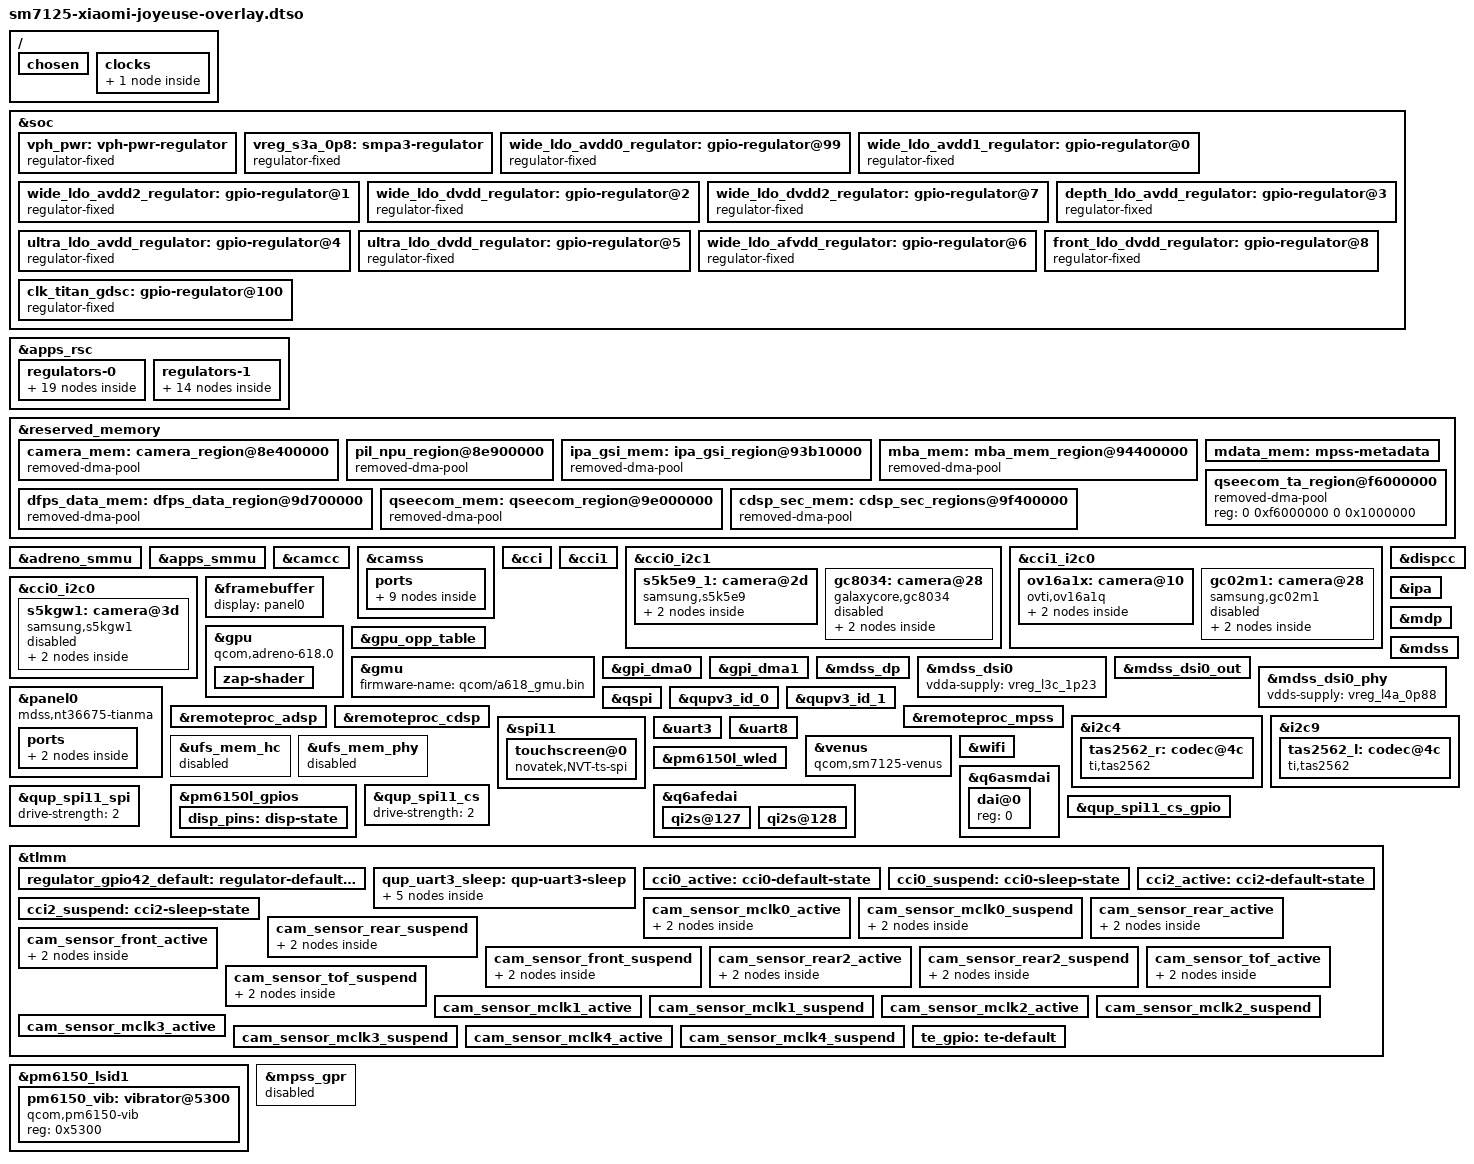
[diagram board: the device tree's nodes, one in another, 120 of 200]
// SPDX-License-Identifier: (GPL-2.0+ OR MIT)

/dts-v1/;

#if 0
/* dt overlay */
/plugin/;
#else
#include "sm7125-xiaomi-joyeuse.dts"
#endif
#include "sm7125-xiaomi-joyeuse-overlay.dtsi"

/ {
	chosen {
		#address-cells = <2>;
		#size-cells = <2>;
		ranges;

		//TODO: remove unneeded once all sorta out.
		bootargs = "pd_ignore_unused no_console_suspend kpti=off nokaslr ignore_loglevel clk_ignore_unused";

		stdout-path = "serial0:115200n8";
	};

	//reserved_memory: reserved_memory {};

	/* place-holder incase need a new fixed clk */
	clocks: clocks {
	        clk_titan_gdsc {
			compatible = "fixed-clock";
			clock-frequency = <38400000>;
			#clock-cells = <0>;
	        };
	};
};

&soc {
	vph_pwr: vph-pwr-regulator {
		compatible = "regulator-fixed";
		regulator-name = "vph_pwr";
		regulator-min-microvolt = <3700000>;
		regulator-max-microvolt = <3700000>;
	};

	vreg_s3a_0p8: smpa3-regulator {
		compatible = "regulator-fixed";
		regulator-name = "vreg_s3a_0p8";

		regulator-min-microvolt = <800000>;
		regulator-max-microvolt = <800000>;
		regulator-always-on;
		vin-supply = <&vph_pwr>;
	};
#if 1
	wide_ldo_avdd0_regulator: gpio-regulator@99 { //AVDD0 2.9V //AVDD0_2.8V
                compatible = "regulator-fixed";
                regulator-name = "wide_ldo_avdd0_regulator";
                regulator-min-microvolt = <2800000>;
                regulator-max-microvolt = <2800000>;
                regulator-enable-ramp-delay = <100>;
                enable-active-high;
                gpio = <&pm6150l_gpios 4 0>; /* schematic not connected */
                vin-supply = <&vreg_bob>;
        };

        wide_ldo_avdd1_regulator: gpio-regulator@0 { //AVDD1 2.9V //AVDD0_2.8V
                compatible = "regulator-fixed";
                regulator-name = "wide_ldo_avdd1_regulator";
                regulator-min-microvolt = <2800000>;
                regulator-max-microvolt = <2800000>;
                regulator-enable-ramp-delay = <100>;
                enable-active-high;
                gpio = <&pm6150l_gpios 9 0>; 
		/* 
		* another gpio4 called avdd1_2p8 but schematic not connected 
		* and the name is swapped to avdd0 accordingly.
		*/
                vin-supply = <&vreg_bob>;
        };

        wide_ldo_avdd2_regulator: gpio-regulator@1 { //AVDD2 1.8V //2M_DVDDIO_1.8V?
                compatible = "regulator-fixed";
                regulator-name = "wide_ldo_avdd2_regulator";
                regulator-min-microvolt = <1800000>;
                regulator-max-microvolt = <1800000>;
                regulator-enable-ramp-delay = <100>;
                enable-active-high;
                gpio = <&pm6150l_gpios 12 0>; //for P0,demo is tlmm 63 //TODO
                vin-supply = <&vreg_bob>; //TODO
        };

        wide_ldo_dvdd_regulator: gpio-regulator@2 { //DVDD 1.2V
                compatible = "regulator-fixed";
                regulator-name = "wide_ldo_dvdd_regulator";
                regulator-min-microvolt = <1200000>;
                regulator-max-microvolt = <1200000>;
                regulator-enable-ramp-delay = <100>;
                enable-active-high;
                gpio = <&tlmm 42 0>;
                vin-supply = <&vreg_s5a>;//48M pm6150_s5
        };

        wide_ldo_dvdd2_regulator: gpio-regulator@7 { //DVDD2 1.05V
                compatible = "regulator-fixed";
                regulator-name = "wide_ldo_dvdd2_regulator";
                regulator-min-microvolt = <1050000>;
                regulator-max-microvolt = <1050000>;
                regulator-enable-ramp-delay = <100>;
                enable-active-high;
                gpio = <&tlmm 42 0>;
                vin-supply = <&vreg_s8c>;//64M pm6150l_s8 + pm6150_s5a
        };

        depth_ldo_avdd_regulator: gpio-regulator@3 { //depth AVDD 2.8V
                compatible = "regulator-fixed";
                regulator-name = "depth_ldo_avdd_regulator";
                regulator-min-microvolt = <2800000>;
                regulator-max-microvolt = <2800000>;
                regulator-enable-ramp-delay = <100>;
                enable-active-high;
                gpio = <&tlmm 43 0>;
                vin-supply = <&vreg_bob>;
        };

        ultra_ldo_avdd_regulator: gpio-regulator@4 { //ultra AVDD 2.8V
                compatible = "regulator-fixed";
                //reg = <0x04 0x00>;
                regulator-name = "ultra_ldo_avdd_regulator";
                regulator-min-microvolt = <2800000>;
                regulator-max-microvolt = <2800000>;
                regulator-enable-ramp-delay = <100>;
                enable-active-high;
                gpio = <&pm6150l_gpios 8 0>;//for p0 main band
                vin-supply = <&vreg_bob>;
        };

        ultra_ldo_dvdd_regulator: gpio-regulator@5 { //ultra DVDD 2.8V
                compatible = "regulator-fixed";
                regulator-name = "ultra_ldo_dvdd_regulator";
                regulator-min-microvolt = <1200000>;
                regulator-max-microvolt = <1200000>;
                regulator-enable-ramp-delay = <100>;
                enable-active-high;
                gpio = <&tlmm 72 0>;
                vin-supply = <&vreg_s5a>;
        };

        wide_ldo_afvdd_regulator: gpio-regulator@6 { //AFVDD 2.8V
                compatible = "regulator-fixed";
                regulator-name = "wide_ldo_afvdd_regulator";
                regulator-min-microvolt = <2800000>;
                regulator-max-microvolt = <2800000>;
                regulator-enable-ramp-delay = <100>;
                enable-active-high;
                gpio = <&pm6150l_gpios 6 0>;
                vin-supply = <&vreg_bob>; //TODO
        };

        front_ldo_dvdd_regulator: gpio-regulator@8 { //dvdd1.1v-20
                compatible = "regulator-fixed";
                regulator-name = "front_ldo_dvdd_regulator";
                regulator-min-microvolt = <1050000>;
                regulator-max-microvolt = <1050000>;
                regulator-enable-ramp-delay = <100>;
                enable-active-high;
                gpio = <&tlmm 117 0>;
                vin-supply = <&vreg_s5a>;
        };
#endif
        clk_titan_gdsc: gpio-regulator@100 { //dummy gdsc
                compatible = "regulator-fixed";
                //reg = <0x08 0x00>;
                regulator-name = "clk_titan_gdsc";
                regulator-min-microvolt = <1050000>;
                regulator-max-microvolt = <1050000>;
                regulator-enable-ramp-delay = <100>;
        };
};

&apps_rsc {
	regulators-0 {	
		vdd-s1-supply = <&vph_pwr>;
		vdd-s2-supply = <&vph_pwr>;
		vdd-s3-supply = <&vph_pwr>;
		vdd-s4-supply = <&vph_pwr>;
		vdd-s5-supply = <&vph_pwr>;

		vreg_s4a_1p1: smps4 {
			regulator-min-microvolt = <824000>;
			regulator-max-microvolt = <1120000>;
		};

		vreg_s5a:
		vreg_s5a_2p0: smps5 {
			regulator-min-microvolt = <1744000>;
			regulator-max-microvolt = <2040000>;
		};

		vreg_l1a_1p2: ldo1 {
			regulator-min-microvolt = <1178000>;
			regulator-max-microvolt = <1256000>;
		};

		vreg_l2a_1p0: ldo2 {
			regulator-min-microvolt = <944000>;
			regulator-max-microvolt = <1056000>;
		};

		vdda_pll_cc_ebi01:
		vreg_l3a_1p0: ldo3 {
			regulator-min-microvolt = <968000>;
			regulator-max-microvolt = <1064000>;
		};

		vdd_qlink_lv:
		vdd_qlink_lv_ck:
		vdd_usb_hs_core:
		vdda_mipi_csi0_0p9:
		vdda_mipi_csi1_0p9:
		vdda_mipi_csi2_0p9:
		vdda_mipi_csi3_0p9:
		vdda_mipi_dsi0_pll:
		vdda_mipi_dsi1_pll:
		vdda_qrefs_0p9:
		vdda_ufs_core:
		vdda_usb_ss_dp_core:
		vreg_l4a_0p88: ldo4 {
			regulator-min-microvolt = <824000>;
			regulator-max-microvolt = <924000>;
		};

		vreg_l5a_2p7: ldo5 {
			regulator-min-microvolt = <2600000>;
			regulator-max-microvolt = <2800000>;
		};

		vreg_l6a_1p2: ldo6 {
			regulator-min-microvolt = <568000>;
			regulator-max-microvolt = <648000>;			
		};

		vdd_wcss_cx:
		vreg_l9a_0p8: ldo9 {
			regulator-min-microvolt = <624000>;
			regulator-max-microvolt = <800000>;
		};

		vddpx_3:
		vreg_l10a_1p8: ldo10 {
			regulator-min-microvolt = <1800000>;
			regulator-max-microvolt = <1832000>;
		};

		vdd_qfprom:
		vdda_apc1_cs_1p8:
		vdda_qrefs_1p8:
		vdda_usb_hs_1p8:
		vddpx_11:
		vreg_l11a_1p8: ldo11 {
			regulator-min-microvolt = <1696000>;
			regulator-max-microvolt = <1904000>;
		};

		vreg_l12a_1p8: ldo12 {
			regulator-min-microvolt = <1696000>;
			regulator-max-microvolt = <1952000>;
		};

		/* 3p0 <- 800ohm -> 1p8 */
		vreg_l13a_1p8: ldo13 {
			regulator-min-microvolt = <1696000>;
			regulator-max-microvolt = <1904000>;
		};

		vreg_l14a_1p8: ldo14 {
			regulator-min-microvolt = <1720000>;
			regulator-max-microvolt = <1832000>;
		};

		vreg_l15a_1p8: ldo15 {
			regulator-min-microvolt = <1696000>;
			regulator-max-microvolt = <1904000>;
		};

		vreg_l16a_2p8: ldo16 {
			regulator-min-microvolt = <2496000>;
			regulator-max-microvolt = <3304000>;
		};

		vdda_usb_hs_3p1:
		vreg_l17a_3p1: ldo17 {
			regulator-min-microvolt = <2920000>;
			regulator-max-microvolt = <3232000>;
		};

		vreg_l18a_2p8: ldo18 {
                        /* 
			 * make it align with l13a a fixed 1p8 since serial with 2x 200ohm
			 */
			regulator-min-microvolt = <1696000>;
			regulator-max-microvolt = <1904000>;
		};

		vreg_l19a_2p85: ldo19 {
			regulator-min-microvolt = <2944000>;
			regulator-max-microvolt = <3304000>;
		};
	};

	regulators-1 {
		vdd-s1-supply = <&vph_pwr>;
		vdd-s2-supply = <&vph_pwr>;
		vdd-s3-supply = <&vph_pwr>;
		vdd-s4-supply = <&vph_pwr>;
		vdd-s5-supply = <&vph_pwr>;
		vdd-s6-supply = <&vph_pwr>;
		vdd-s7-supply = <&vph_pwr>;
		vdd-s8-supply = <&vph_pwr>;

		vreg_s1c_1p13: smps1 {
			regulator-min-microvolt = <1000000>;
			regulator-max-microvolt = <1200000>;
		};

		vreg_s8c:
		vreg_s8c_1p35: smps8 {
			regulator-min-microvolt = <1120000>;
			regulator-max-microvolt = <1408000>;
		};

		vreg_l1c_1p8: ldo1 {
			regulator-min-microvolt = <1616000>;
			regulator-max-microvolt = <1984000>;
		};

		vdd_wcss_adc_dac:
		vreg_l2c_1p3: ldo2 {
			regulator-min-microvolt = <1168000>;
			regulator-max-microvolt = <1304000>;
		};

		vdda_csi0_1p25:
		vdda_csi1_1p25:
		vdda_csi2_1p25:
		vdda_csi3_1p25:
		vdda_hv_ebi0:
		vdda_mipi_dsi0_1p2:
		vdda_mipi_dsi1_1p2:
		vdda_ufs_1p2:
		vdda_usb_ss_dp_1p2:
		vddpx_10:
		vreg_l3c_1p23: ldo3 {
			regulator-min-microvolt = <1144000>;
			regulator-max-microvolt = <1304000>;
		};

		vddpx_5:
		vreg_l4c_1p8: ldo4 {
			regulator-min-microvolt = <1648000>;
			regulator-max-microvolt = <3304000>;
		};

		vddpx_6:
		vreg_l5c_1p8: ldo5 {
			regulator-min-microvolt = <1648000>;
			regulator-max-microvolt = <3304000>;
		};

		vddpx_2:
		vreg_l6c_3p0: ldo6 {
			regulator-min-microvolt = <1648000>;
			regulator-max-microvolt = <3304000>;
		};

		vreg_l7c_3p0: ldo7 {
			regulator-min-microvolt = <3000000>;
			regulator-max-microvolt = <3312000>;
			regulator-always-on;
		};

		vreg_l8c_1p8: ldo8 {
			regulator-min-microvolt = <1800000>;
			regulator-max-microvolt = <1900000>;
		};

		vreg_l9c_3p1: ldo9 {
			regulator-min-microvolt = <2950000>;
			regulator-max-microvolt = <3100000>;
		};

		vreg_l10c_3p3: ldo10 {
			regulator-min-microvolt = <3200000>;
			regulator-max-microvolt = <3400000>;
		};

		vreg_l11c_3p3: ldo11 {
			regulator-min-microvolt = <3000000>;
			regulator-max-microvolt = <3400000>;
		};

		vreg_bob: bob {
			regulator-min-microvolt = <3296000>;
			regulator-max-microvolt = <3960000>;
		};
	};
};

&reserved_memory {
		camera_mem: camera_region@8e400000 {
			compatible = "removed-dma-pool";
			no-map;
			reg = <0x00 0x8e400000 0x00 0x500000>;
		};
		
		pil_npu_region@8e900000 {
			compatible = "removed-dma-pool";
			no-map;
			reg = <0x00 0x8e900000 0x00 0x500000>;
		};

		ipa_gsi_mem: ipa_gsi_region@93b10000 {
			compatible = "removed-dma-pool";
			no-map;
			reg = <0x00 0x93b10000 0x00 0x5000>;
		};

		mba_mem: mba_mem_region@94400000 {
			compatible = "removed-dma-pool";
			reg = <0x0 0x94400000 0x0 0x200000>;
			no-map;
		};

		dfps_data_mem: dfps_data_region@9d700000 {
			reg = <0x00 0x9d700000 0x00 0x100000>;
			compatible = "removed-dma-pool";
			no-map;
		};

		qseecom_mem: qseecom_region@9e000000 {
			compatible = "removed-dma-pool";
			no-map;
			reg = <0x00 0x9e000000 0x00 0x1400000>;
		};
		
		cdsp_sec_mem: cdsp_sec_regions@9f400000 {
			compatible = "removed-dma-pool";
			no-map;
			reg = <0x00 0x9f400000 0x00 0x1e00000>;
		};

		mdata_mem: mpss-metadata {
			alloc-ranges = <0x0 0xa0000000 0x0 0x20000000>;
			size = <0x0 0x4000>;
			no-map;
		};

                qseecom_ta_region@f6000000 {
                        compatible = "removed-dma-pool";
                        reg = <0 0xf6000000 0 0x1000000>;
                };
};

&adreno_smmu {
        status = "okay";
};

&apps_smmu {
        status = "okay";
};

&camcc {
        status = "okay";
};

&camss {
	vdda-phy-supply = <&vreg_l4a_0p88>;
	vdda-pll-supply = <&vreg_l3c_1p23>;

	status = "okay";

	ports {
		#address-cells = <1>;
		#size-cells = <0>;

		//confirmed
		port@0 {
			csiphy0_ep0: endpoint@0 {
				data-lanes = <0 1>;
				remote-endpoint = <&gc8034_ep0>;
				status = "disabled";
			};		
		};
		
		port@1 {
			csiphy1_ep0: endpoint@0 {
				/* TODO: check! */
				data-lanes = <0 1 2>;
				remote-endpoint = <&s5kgw1_ep0>;
				status = "disabled";
			};
		};

		//confirmed
		port@2 {
                        csiphy2_ep1: endpoint@1 {
                                data-lanes = <0 1 2 3>;
                                remote-endpoint = <&s5k5e9_ep0>;
				status = "okay";
                        };

                        csiphy2_ep0: endpoint@0 {
				/* TODO: check with log */
                                data-lanes = <0 1 2>;
                                remote-endpoint = <&gc02m1_ep0>;
				status = "disabled";
                        };
		};

		//confirmed
		port@3 {
			csiphy3_ep0: endpoint@0 {
                                data-lanes = <0 1 2 3>;
                                remote-endpoint = <&ov16a1x_ep0>;
				status = "disabled";
                        };
                };
	};
};

&cci {
        status = "okay";
};

&cci1 {
        status = "okay";
};

#if 0
[   18.731285] CAM_INFO: CAM-SENSOR: cam_sensor_driver_cmd: 742 Probe success,slot:0,slave_addr:0x7a,sensor_id:0x971
[   19.064560] CAM_INFO: CAM-SENSOR: cam_sensor_driver_cmd: 742 Probe success,slot:1,slave_addr:0x6e,sensor_id:0x2e0
[   18.954235] CAM_INFO: CAM-SENSOR: cam_sensor_driver_cmd: 742 Probe success,slot:2,slave_addr:0x20,sensor_id:0x1641
[   19.162159] CAM_INFO: CAM-SENSOR: cam_sensor_driver_cmd: 742 Probe success,slot:3,slave_addr:0x6e,sensor_id:0x8044
[   19.296172] CAM_INFO: CAM-SENSOR: cam_sensor_driver_cmd: 742 Probe success,slot:4,slave_addr:0x5a,sensor_id:0x559b

 CAM_DBG: CAM-EEPROM: cam_eeprom_read_memory: 51: slave-addr = 0x0
 CAM_DBG: CAM-EEPROM: cam_eeprom_read_memory: 51: slave-addr = 0x6E
 CAM_DBG: CAM-EEPROM: cam_eeprom_read_memory: 51: slave-addr = 0xA0
 CAM_DBG: CAM-EEPROM: cam_eeprom_read_memory: 51: slave-addr = 0xA2
 CAM_DBG: CAM-EEPROM: cam_eeprom_read_memory: 51: slave-addr = 0xA8

[   47.248726] CAM_DBG: CAM-ACTUATOR: cam_actuator_slaveInfo_pkt_parser: 237: Slave addr: 0x18 Freq Mode: 1
#endif

/* sensor 4 yyds */
&cci0_i2c1 {
        status = "okay";

#if 0
id:0x5a:0x559b//s5k5e9
sensor:4 //reset3 //tlmm 24, //MCLK2 (gpio15)
  cci-master = <1>; // port [0..1]
  cci-device = <0>; //repersent to i2c_dev
<&pm6150_l13>;
<&ultra_ldo_avdd_regulator>;
<&ultra_ldo_dvdd_regulator>;
<&titan_top_gdsc>;
regulator-names = "cam_vio", "cam_vana", "cam_vdig", "cam_clk";
csiphy-sd-index = <2>;
[   45.672624] CAM_DBG: CAM-ISP: cam_csid_ppi_init_hw: 212: lane_cfg  0x3210 | num_lanes  0x4 | lane_type 0x0
[   37.714675] CAM_INFO: CAM-ISP: cam_ife_csid_set_csid_clock: 3248 CSID clock rate 96200000
#endif
	
        s5k5e9_1: camera@2d {
			compatible = "samsung,s5k5e9";
			reg = <0x2d>;

			pinctrl-names = "default", "suspend";
			pinctrl-0 = <&cam_sensor_mclk2_active>;
			pinctrl-1 = <&cam_sensor_mclk2_suspend>;

			clocks = <&camcc CAM_CC_MCLK2_CLK>;
			clock-names = "xvclk";
			clock-frequency = <19200000>;
			assigned-clocks = <&camcc CAM_CC_MCLK2_CLK>;
			assigned-clock-rates = <19200000>;

			vdda-supply = <&vreg_l13a_1p8>;
			vddd-supply = <&ultra_ldo_avdd_regulator>;
			vdddo-supply = <&ultra_ldo_dvdd_regulator>;

                        enable-gpios = <&tlmm 24 GPIO_ACTIVE_LOW>;

			status = "okay";

                port {
                        s5k5e9_ep0: endpoint {
                                link-frequencies = /bits/ 64
					<24000000 480000000>;
                                data-lanes = <0 1 2 3>;
                                remote-endpoint = <&csiphy2_ep1>;
				status = "okay";
                        };
                };
	};
};

/* sensor 2 */
&cci1_i2c0 {
	status = "okay";
	/* cci 0 sensor 3 */

#if 0
/* front cam*/
id:0x20:0x1641//ov16a1q
sensor:2 //reset2 //tlmm 32 //mclk0 (gpio13)
  cci-master = <0>;
  cci-device = <1>;
<&pm6150_l13>;
<&ultra_ldo_avdd_regulator>;//AVDD 16M/20M
<&ultra_ldo_dvdd_regulator>;//DVDD 16M
<&wide_ldo_dvdd2_regulator>; //DVDD 20M
<&front_ldo_dvdd_regulator>; //DVDD NEW-BOM 1.1V OV32
<&titan_top_gdsc>;
regulator-names = "cam_vio", "cam_vana", "cam_vdig","cam_v_custom1","cam_v_custom2",
                        "cam_clk";
<&pm6150l_gpios 4 0>;
[  209.817067] CAM_DBG: CAM-ISP: cam_csid_ppi_init_hw: 212: lane_cfg  0x3210 | num_lanes  0x4 | lane_type 0x0
[  154.501391] CAM_INFO: CAM-ISP: cam_ife_csid_set_csid_clock: 3248 CSID clock rate 96200000
csiphy-sd-index = <3>;
#endif
	ov16a1x: camera@10 {
		compatible = "ovti,ov16a1q", "ovti,ov16a1x", "ovti,ov16a10";
		reg = <0x10>;

		reset-gpios = <&tlmm 32 GPIO_ACTIVE_HIGH>;
		enable-gpios = <&tlmm 32 GPIO_ACTIVE_HIGH>;

		pinctrl-names = "default", "suspend";
		pinctrl-0 = <&cam_sensor_mclk0_active>;
		pinctrl-1 = <&cam_sensor_mclk0_suspend>;

		clocks = <&camcc CAM_CC_MCLK0_CLK>;
		clock-names = "xvclk";
		clock-frequency = <19200000>;
		assigned-clocks = <&camcc CAM_CC_MCLK0_CLK>;
		assigned-clock-rates = <19200000>;

		vdda-supply = <&vreg_l13a_1p8>;
		vddd-supply = <&ultra_ldo_avdd_regulator>;//AVDD 16M/20M
		vdddo-supply = <&ultra_ldo_dvdd_regulator>;//DVDD 16M
		vddc-supply = <&wide_ldo_dvdd2_regulator>; //DVDD 20M
		vddd1-supply = <&front_ldo_dvdd_regulator>; //DVDD NEW-BOM 1.1V OV32

		status = "okay";

                port {
                        ov16a1x_ep0: endpoint {
                                link-frequencies = /bits/ 64
					<24000000 480000000>;
                                data-lanes = <0 1 2 3>;
                                remote-endpoint = <&csiphy3_ep0>;
				status = "okay";
                        };
                };
	};
};

/* sensor 3 */
&cci0_i2c1 {
	status = "okay";
#if 0
id:0x6e:0x8044//gc8034 >> i2cdetect as addr 0x51
sensor:3 //reset0 //tlmm 30  //MCLK4 (gpio23)
  cci-master = <1>;
  cci-device = <0>;
<&pm6150_l13>;
<&ultra_ldo_avdd_regulator>;
<&ultra_ldo_dvdd_regulator>;
<&titan_top_gdsc>;
regulator-names = "cam_vio", "cam_vana", "cam_vdig", "cam_clk";
regulator : <&pm6150l_gpios 4 0>
[   34.152935] CAM_DBG: CAM-ISP: cam_csid_ppi_init_hw: 212: lane_cfg  0x10 | num_lanes  0x2 | lane_type 0x0
[   48.205835] CAM_INFO: CAM-ISP: cam_ife_csid_set_csid_clock: 3248 CSID clock rate 146400000
[   48.214952] CAM_DBG: CAM-CPAS: cam_cpas_hw_start: 1057: client=[0][csiphy][0] streamon_clients=7
csiphy-sd-index = <0>;
#endif
	gc8034: camera@28 {
		compatible = "galaxycore,gc8034";
		reg = <0x28>;

		reset-gpios = <&tlmm 30 GPIO_ACTIVE_HIGH>;
		enable-gpios = <&tlmm 30 GPIO_ACTIVE_HIGH>;
		
		pinctrl-names = "default", "suspend";
		pinctrl-0 = <&cam_sensor_mclk4_active>;
		pinctrl-1 = <&cam_sensor_mclk4_suspend>;

		clocks = <&camcc CAM_CC_MCLK4_CLK >;
		clock-names = "xvclk";
		clock-frequency = <19200000>;
		assigned-clocks = <&camcc CAM_CC_MCLK4_CLK>;
		assigned-clock-rates = <19200000>;

		vdda-supply = <&vreg_l13a_1p8>;
		vddd-supply = <&ultra_ldo_avdd_regulator>;
		vdddo-supply = <&ultra_ldo_dvdd_regulator>;
		vddc-supply = <&wide_ldo_avdd0_regulator>;

		status = "disabled";

		port {
				gc8034_ep0: endpoint {
						link-frequencies = /bits/ 64
								<360000000 180000000>;
						data-lanes = <0 1>;
						remote-endpoint = <&csiphy0_ep0>;
				};
		};
	};
};

/* sensor 1 */
&cci1_i2c0 {
	status = "okay";
#if 0
id:0x6e:0x2e0//gc02m1 >> i2cdetect as addr 0x51
sensor:1 //reset2 //tlmm 29 //mclk3 (gpio16)
  cci-master = <0>;
  cci-device = <1>;
<&wide_ldo_avdd2_regulator>;
<&depth_ldo_avdd_regulator>;
<&titan_top_gdsc>;
"cam_vio", "cam_vana","cam_clk";
csiphy-sd-index = <2>;

#endif
	gc02m1: camera@28 {
		compatible = "samsung,gc02m1";
		reg = <0x28>;

		reset-gpios = <&tlmm 29 GPIO_ACTIVE_HIGH>;
		enable-gpios = <&tlmm 29 GPIO_ACTIVE_HIGH>;
		
		pinctrl-names = "default", "suspend";
		pinctrl-0 = <&cam_sensor_mclk3_active>;
		pinctrl-1 = <&cam_sensor_mclk3_suspend>;

		clocks = <&camcc CAM_CC_MCLK3_CLK >;
		clock-names = "xvclk";
		clock-frequency = <19200000>;
		assigned-clocks = <&camcc CAM_CC_MCLK3_CLK>;
		assigned-clock-rates = <19200000>;

		//vdda-supply = <&vreg_l13a_1p8>;
		vddd-supply = <&wide_ldo_avdd2_regulator>;
		vdda-supply = <&depth_ldo_avdd_regulator>;

		status = "disabled";

		port {
			gc02m1_ep0: endpoint {
				link-frequencies = /bits/ 64
					<480000000 24000000>;
				/* TODO: seemed 0x210, logged with gw1 sensor log */
				data-lanes = <0 1 2>;
				remote-endpoint = <&csiphy2_ep0>;
			};
		};
	};
};

/* sensor 0 */
&cci0_i2c0 {
	status = "okay";
#if 0
id:0x7a:0x971
sensor:0 //reset1 //tlmm 25 //mclk1 (gpio14)
cci-master:0
cci-dev:0
<&wide_ldo_avdd1_regulator>; //AVDD1 48M/64M
<&wide_ldo_dvdd_regulator>; //DVDD 48M
<&pm6150_l13>;//IOVDD
<&titan_top_gdsc>;
<&wide_ldo_avdd2_regulator>; //AVDD 1.8V-48M
<&wide_ldo_dvdd2_regulator>; //DVDD 64M
regulator-names = "cam_vana", "cam_vdig", "cam_vio",
                        "cam_clk", "cam_v_custom1", "cam_v_custom2";
csiphy-sd-index = <1>;
#endif
        s5kgw1: camera@3d {
                compatible = "samsung,s5kgw1";
                reg = <0x3d>;

                reset-gpios = <&tlmm 25 GPIO_ACTIVE_LOW>;
                enable-gpios = <&tlmm 25 GPIO_ACTIVE_LOW>;

                pinctrl-names = "default", "suspend";
                pinctrl-0 = <&cam_sensor_mclk1_active>;
                pinctrl-1 = <&cam_sensor_mclk1_suspend>;

                clocks = <&camcc CAM_CC_MCLK1_CLK >;
                clock-names = "xvclk";
                clock-frequency = <19200000>;
                assigned-clocks = <&camcc CAM_CC_MCLK1_CLK>;
                assigned-clock-rates = <19200000>;

		vdda-supply = <&vreg_l13a_1p8>;//IOVDD
		vddd-supply = <&wide_ldo_avdd1_regulator>; //AVDD1 48M/64M
		vdddo-supply = <&wide_ldo_dvdd_regulator>; //DVDD 48M
		vddc-supply = <&wide_ldo_avdd2_regulator>; //AVDD 1.8V-48M
		vdddo1-supply =<&wide_ldo_dvdd2_regulator>; //DVDD 64M

                status = "disabled";

                port {
                        s5kgw1_ep0: endpoint {
				/* TODO: check clk */
                                link-frequencies = /bits/ 64
                                        <480000000 24000000>;
                                /* TODO: seemed 0x210, logged with gw1 sensor log */
                                data-lanes = <0 1 2>;
                                remote-endpoint = <&csiphy1_ep0>;
                        };
                };
	};
};

&dispcc {
	status = "okay";
};

&framebuffer {
        display = <&panel0>;
        status = "okay";
};


&gpu {
	compatible = "qcom,adreno-618.0", "qcom,adreno";
	firmware-name = "qcom/sm7125/miatoll/a615_zap.mbn";

	status = "okay";

	zap-shader {
			memory-region = <&gpu_mem>;
			firmware-name = "qcom/sm7125/miatoll/a615_zap.mbn";
	};
};

&gpu_opp_table {
	/* those are too high freq */
	/delete-node/ opp-825000000;
	/delete-node/ opp-800000000;
        /delete-node/ opp-650000000;

	/* those are too slow */
//        /delete-node/ opp-430000000 ;
        /delete-node/ opp-355000000 ;
        /delete-node/ opp-267000000 ;
        /delete-node/ opp-180000000 ;
};

&gmu {
	firmware-name = "qcom/a618_gmu.bin";
	status = "okay";
};

&gpi_dma0 {
	status = "okay";
};

&gpi_dma1 {
	status = "okay";
};

&ipa {
	qcom,gsi-loader = "self";
	memory-region = <&ipa_fw_mem>;
	firmware-name = "qcom/sm7125/miatoll/ipa_fws.mbn";

	status = "okay";
};

&mdp {
	// TODO: check if mdss or mdp hold this memory
//	memory-region = <&cont_splash_mem>;

	status = "okay";
};

&mdss {
	// TODO: check if mdss or mdp hold this memory
//	memory-region = <&cont_splash_mem>;
	status = "okay";
};

&mdss_dp {
        status = "okay";
};

&mdss_dsi0 {
	vdda-supply = <&vreg_l3c_1p23>;
	status = "okay";
};

&mdss_dsi0_out {
	remote-endpoint = <&panel0_in>;
	data-lanes = <0 1 2 3>;

	status = "okay";
};

&mdss_dsi0_phy {
	vdds-supply = <&vreg_l4a_0p88>;

	status = "okay";
};

&panel0 {
	compatible = "mdss,nt36675-tianma", 
			"mdss,nt36675-tianma-fhd";

	reg = <0>;
	
	/* TODO: check vreg l3c/l3a */
	//vdda-supply = <&vreg_l3c_1p23>; //from downstream, need to double check
	//vdd3p3-supply = <&vreg_l18a_3p0>;
	//vddio-supply = <&vreg_l13a_1p8>; //from sm7150-xiaomi-common.dtsi
	vddio-supply = <&vreg_l18a_3p0>;

#if 0
	/* 
		display_sde.dtsi
			vddio-supply = <&L13A>;
			vdda-3p3-supply = <&L18A>;
		---
		cust-atoll-sde-display.dtsi
			/delete-property/ vdda-3p3-supply;

		        vddio-supply = <&L18A>;
	*/

	lab-supply = <&lab>;
	ibb-supply = <&ibb>;
#endif
	backlight = <&pm6150l_wled>;

	pinctrl-names = "default", "te_pin"; //TODO: need to figure out how to handle te_pin
	pinctrl-0 = <&disp_pins>;
        pinctrl-1 = <&te_gpio>;

	/* according to panel-nt36675-tianma.c this gpio is finally set to low */
	reset-gpios = <&pm6150l_gpios 3 GPIO_ACTIVE_LOW>;
	//disp-te-gpio = <&tlmm 10 GPIO_ACTIVE_LOW>;

	status = "okay";

	ports {
		#address-cells = <1>;
		#size-cells = <0>;
		port@0 {
			reg = <0>;
			panel0_in: endpoint {
				remote-endpoint = <&mdss_dsi0_out>;
			};
		};
	};
};


&qspi {
	pinctrl-names = "default";
	pinctrl-0 = <&qspi_clk &qspi_cs0 &qspi_data0 &qspi_data1>;
	
	status = "okay";
};

&qupv3_id_0 {
	status = "okay";
};

&qupv3_id_1 {
	status = "okay";
};

&remoteproc_adsp {
	firmware-name = "qcom/sm7125/miatoll/adsp.mbn";
	memory-region = <&adsp_mem>;

	status = "okay";
};

&remoteproc_cdsp {
	firmware-name = "qcom/sm7125/miatoll/cdsp.mbn";
	memory-region = <&cdsp_mem>;

	status = "okay";
};

&remoteproc_mpss {
	firmware-name = "qcom/sm7125/miatoll/modem.mbn";
	memory-region = <&mpss_mem>;

	status = "okay";
};

&i2c4 {
	status = "ok";
                tas2562_r: codec@4c {
                        compatible = "ti,tas2562";
                        reg = <0x4c>;
                        #sound-dai-cells = <1>;
                        interrupt-parent = <&tlmm>;
                        interrupts = <33 0>;
                        shutdown-gpios = <&tlmm 33 0>;
			reset-gpio = <&tlmm 51 0>;
                        sound-name-prefix = "Right"; //??
                        ti,vmon-slot-no = <2>;
                        ti,imon-slot-no = <0>;
                };
};

&i2c9 {
	status = "ok";
                tas2562_l: codec@4c {
                        compatible = "ti,tas2562";
                        reg = <0x4c>;
                        #sound-dai-cells = <1>;
                        interrupt-parent = <&tlmm>;
                        interrupts = <33 0>;
                        shutdown-gpios = <&tlmm 33 0>;
                        reset-gpio = <&tlmm 51 0>;
                        sound-name-prefix = "Right"; //??
                        ti,vmon-slot-no = <2>;
                        ti,imon-slot-no = <0>;
                };
};

&spi11 {
	status = "okay";

	touchscreen@0 {
		compatible = "novatek,NVT-ts-spi", "novatek,NVT-ts-spi", "novatek,nt36675-spi";
		reg = <0>;

		/* caught from joyeuse dtb*/
		spi-max-frequency = <4000000>;

		/* ts->irq report 194 */
		/* interrupts = <&tlmm 194 IRQ_TYPE_EDGE_FALLING>; */
		/* interrupt= <&tlmm 13 2>; */ //dtb specified, but GPIO13 is CAM_MCLK0

		novatek,reset-gpio = <&tlmm 8 0x00>;
		novatek,irq-gpio = <&tlmm 9 0x2001>;

		/* 672C */
		novatek,swrst-n8-addr = <0x03F0FE>;
		novatek,spi-rd-fast-addr = <0x03F310>;

		reset-gpio = <&tlmm 8 0x00>;
                /* dtb show <&tlmm 13 2>*/
		irq-gpio = <&tlmm 9 0x2001>;

/*
                touch_ibb-supply = <0x241>; //lcdb_ncp
                touch_lab-supply = <0x240>; //qcom,qpnp-lcdb-regulator ldo
                touch_vddio-supply = <0x33c>; //pm6150_l18
*/

		vio-supply = <&vreg_l18a_3p0>;
		vdd-supply = <&vreg_l18a_3p0>;

		panel = <&panel0>;

		status = "okay";
	};
};

&uart3 {
	/delete-property/interrupts;
	interrupts-extended = <&intc GIC_SPI 604 IRQ_TYPE_LEVEL_HIGH>,
				<&tlmm 41 IRQ_TYPE_EDGE_FALLING>;

	pinctrl-names = "default", "sleep";
	pinctrl-1 = <&qup_uart3_sleep>;

	status = "okay";
};

&uart8 {
	status = "okay";
};


&ufs_mem_hc {
	vcc-supply = <&vreg_l19a_3p0>;
	vcc-max-microamp = <600000>;
	vccq2-supply = <&vreg_l12a_1p8>;
	vccq2-max-microamp = <600000>;

	status = "okay";
};

&ufs_mem_phy {
	vdda-phy-supply = <&vreg_l4a_0p88>;
	vdda-pll-supply = <&vreg_l3c_1p23>;
	vdda-phy-max-microamp = <62900>;
	vdda-pll-max-microamp = <18300>;

	status = "okay";
};


&venus {
	compatible = "qcom,sm7125-venus", "qcom,sc7180-venus";
	memory-region = <&venus_mem>;
	firmware-name = "qcom/sm7125/miatoll/venus.mbn";

	status = "okay";
};

&wifi {
	vdd-0.8-cx-mx-supply = <&vreg_l9a_0p664>;
	vdd-1.8-xo-supply = <&vreg_l1c_1p8>;
	vdd-1.3-rfa-supply = <&vreg_l2c_1p3>;
	vdd-3.3-ch0-supply = <&vreg_l10c_3p3>;
	vdd-3.3-ch1-supply = <&vreg_l11c_3p3>;

	firmware-name = "qcom/sm7125/miatoll/wlanmdsp.mbn";

        status = "okay";
};

/* PINCTRL - additions to nodes defined in sc7180.dtsi */
&pm6150l_gpios {
	disp_pins: disp-state {
		pins = "gpio3";
		function = PMIC_GPIO_FUNC_FUNC1;
		qcom,drive-strength = <PMIC_GPIO_STRENGTH_MED>;
		power-source = <0>;
		bias-disable;
		output-low;
	};

};

&pm6150l_wled {
	status = "okay";
};

#if 1
&q6afedai {
        qi2s@127 {
                reg = <QUINARY_MI2S_RX>;
                qcom,sd-lines = <0>;
        };

        qi2s@128 {
                reg = <QUINARY_MI2S_TX>;
                qcom,sd-lines = <1>;
        };
};

&q6asmdai {
        dai@0 {
                reg = <0>;
        };
};
#endif

&qup_spi11_spi {
	drive-strength = <2>;
	//bias-disable;
};

&qup_spi11_cs {
	drive-strength = <2>;
	//bias-disable;
};

&qup_spi11_cs_gpio {
	drive-strength = <2>;
	bias-disable;
};

&tlmm {
        regulator_gpio42_default: regulator-default-state {
                pins = "gpio42", "gpio43", "gpio72", "gpio117";
                function = "gpio";
		bias-pull-up;
        };

	qup_uart3_sleep: qup-uart3-sleep {
		pinmux {
			pins = "gpio38", "gpio39",
			       "gpio40", "gpio41";
			function = "gpio";
		};

		pinconf-cts {
			/*
			 * Configure a pull-down on CTS to match the pull of
			 * the Bluetooth module.
			 */
			pins = "gpio38";
			bias-pull-down;
		};

		pinconf-rts {
			/*
			 * Configure pull-down on RTS. As RTS is active low
			 * signal, pull it low to indicate the BT SoC that it
			 * can wakeup the system anytime from suspend state by
			 * pulling RX low (by sending wakeup bytes).
			 */
			 pins = "gpio39";
			 bias-pull-down;
		};

		pinconf-tx {
			/*
			 * Configure pull-up on TX when it isn't actively driven
			 * to prevent BT SoC from receiving garbage during sleep.
			 */
			pins = "gpio40";
			bias-pull-up;
		};

		pinconf-rx {
			/*
			 * Configure a pull-up on RX. This is needed to avoid
			 * garbage data when the TX pin of the Bluetooth module
			 * is floating which may cause spurious wakeups.
			 */
			pins = "gpio41";
			bias-pull-up;
		};
	};

		cci0_active: cci0-default-state {
				/* CLK, DATA */
				function = "cci_i2c";
				pins = "gpio17", "gpio18", "gpio19", "gpio20";
				bias-pull-up; /* PULL UP*/
				drive-strength = <2>; /* 2 MA */
		};

		cci0_suspend: cci0-sleep-state {
				/* CLK, DATA */
				function = "cci_i2c";
				pins = "gpio17", "gpio18", "gpio19", "gpio20";
				bias-pull-down; /* PULL DOWN */
				drive-strength = <2>; /* 2 MA */
		};
#if 0
		cci1_active: cci1-default-state {
				/* CLK, DATA */
				function = "cci_i2c";
				pins = "gpio19", "gpio20";
				bias-pull-up; /* PULL UP*/
				drive-strength = <2>; /* 2 MA */
		};

		cci1_suspend: cci1-sleep-state {
				/* CLK, DATA */
				function = "cci_i2c";
				pins = "gpio19", "gpio20";
				bias-pull-down; /* PULL DOWN */
				drive-strength = <2>; /* 2 MA */
		};
#endif
		cci2_active: cci2-default-state {
				/* CLK, DATA */
				function = "cci_i2c";
				pins = "gpio27", "gpio28";
				bias-pull-up; /* PULL UP*/
				drive-strength = <2>; /* 2 MA */
		};

		cci2_suspend: cci2-sleep-state {
				/* CLK, DATA */
				function = "cci_i2c";
				pins = "gpio27", "gpio28";
				bias-pull-down; /* PULL DOWN */
				drive-strength = <2>; /* 2 MA */
		};

		cam_sensor_mclk0_active: cam_sensor_mclk0_active {
			/* MCLK0 */
			mux {
				pins = "gpio13";
				function = "cam_mclk";
			};

			config {
				pins = "gpio13";
				bias-disable; /* No PULL */
				drive-strength = <2>; /* 2 MA */
			};
		};

		cam_sensor_mclk0_suspend: cam_sensor_mclk0_suspend {
			/* MCLK0 */
			mux {
				pins = "gpio13";
				function = "cam_mclk";
			};

			config {
				pins = "gpio13";
				bias-pull-down; /* PULL DOWN */
				drive-strength = <2>; /* 2 MA */
			};
		};

		cam_sensor_rear_active: cam_sensor_rear_active {
			/* RESET */
			mux {
				pins = "gpio30";
				function = "gpio";
			};

			config {
				pins = "gpio30";
				bias-disable; /* No PULL */
				drive-strength = <2>; /* 2 MA */
			};
		};

		cam_sensor_rear_suspend: cam_sensor_rear_suspend {
			/* RESET */
			mux {
				pins = "gpio30";
				function = "gpio";
			};

			config {
				pins = "gpio30";
				bias-pull-down; /* PULL DOWN */
				drive-strength = <2>; /* 2 MA */
				output-low;
			};
		};

		cam_sensor_front_active: cam_sensor_front_active {
			/* RESET  */
			mux {
				pins = "gpio29";
				function = "gpio";
			};

			config {
				pins = "gpio29";
				bias-disable; /* No PULL */
				drive-strength = <2>; /* 2 MA */
			};
		};

		cam_sensor_front_suspend: cam_sensor_front_suspend {
			/* RESET */
			mux {
				pins = "gpio29";
				function = "gpio";
			};

			config {
				pins = "gpio29";
				bias-pull-down; /* PULL DOWN */
				drive-strength = <2>; /* 2 MA */
				output-low;
			};
		};

		cam_sensor_rear2_active: cam_sensor_rear2_active {
			/* RESET */
			mux {
				pins = "gpio25";
				function = "gpio";
			};

			config {
				pins = "gpio25";
				bias-disable; /* No PULL */
				drive-strength = <2>; /* 2 MA */
			};
		};

		cam_sensor_rear2_suspend: cam_sensor_rear2_suspend {
			/* RESET */
			mux {
				pins = "gpio25";
				function = "gpio";
			};

			config {
				pins = "gpio25";
				bias-pull-down; /* PULL DOWN */
				drive-strength = <2>; /* 2 MA */
				output-low;
			};
		};

		cam_sensor_tof_active: cam_sensor_tof_active {
			/* RESET */
			mux {
				pins = "gpio24";
				function = "gpio";
			};

			config {
				pins = "gpio24";
				bias-disable; /* No PULL */
				drive-strength = <2>; /* 2 MA */
			};
		};

		cam_sensor_tof_suspend: cam_sensor_tof_suspend {
			/* RESET */
			mux {
				pins = "gpio24";
				function = "gpio";
			};

			config {
				pins = "gpio24";
				bias-pull-down; /* PULL DOWN */
				drive-strength = <2>; /* 2 MA */
				output-low;
			};
		};

		cam_sensor_mclk1_active: cam_sensor_mclk1_active {
			/* MCLK1 */
				function = "cam_mclk";
				pins = "gpio14";
				bias-disable; /* No PULL */
				drive-strength = <2>; /* 2 MA */
		};

		cam_sensor_mclk1_suspend: cam_sensor_mclk1_suspend {
			/* MCLK1 */
				function = "cam_mclk";
				pins = "gpio14";
				bias-pull-down; /* PULL DOWN */
				drive-strength = <2>; /* 2 MA */
		};

		cam_sensor_mclk2_active: cam_sensor_mclk2_active {
			/* MCLK2 */
				function = "cam_mclk";
				pins = "gpio15";
				bias-disable; /* No PULL */
				drive-strength = <2>; /* 2 MA */
		};

		cam_sensor_mclk2_suspend: cam_sensor_mclk2_suspend {
			/* MCLK2 */
				function = "cam_mclk";
				pins = "gpio15";
				bias-pull-down; /* PULL DOWN */
				drive-strength = <2>; /* 2 MA */
		};

		cam_sensor_mclk3_active: cam_sensor_mclk3_active {
			/* MCLK3 */
				function = "cam_mclk";
				pins = "gpio16";
				bias-disable; /* No PULL */
				drive-strength = <2>; /* 2 MA */
		};

		cam_sensor_mclk3_suspend: cam_sensor_mclk3_suspend {
			/* MCLK3 */
				function = "cam_mclk";
				pins = "gpio16";
				bias-pull-down; /* PULL DOWN */
				drive-strength = <2>; /* 2 MA */
		};

		cam_sensor_mclk4_active: cam_sensor_mclk4_active {
			/* MCLK4 */

				pins = "gpio23";
				function = "cam_mclk";
				bias-disable; /* No PULL */
				drive-strength = <2>; /* 2 MA */

		};

		cam_sensor_mclk4_suspend: cam_sensor_mclk4_suspend {
			/* MCLK4 */
				function = "cam_mclk";

				pins = "gpio23";
				bias-pull-down; /* PULL DOWN */
				drive-strength = <2>; /* 2 MA */
		};
#if 0
        pmx_ts_active {
                ts_active: ts_active {
                                mux {
                                        pins = "gpio8", "gpio9";
                                        function = "gpio";
                                };

                                config {
                                        pins = "gpio8", "gpio9";
                                        drive-strength = <8>;
                                        bias-pull-up;
                                };
                        };
        };

                pmx_ts_int_suspend {
                        ts_int_suspend: ts_int_suspend {
                                mux {
                                        pins = "gpio9";
                                        function = "gpio";
                                };

                                config {
                                        pins = "gpio9";
                                        drive-strength = <2>;
                                        bias-disable;
                                };
                        };
                };

                pmx_ts_reset_suspend {
                        ts_reset_suspend: ts_reset_suspend {
                                mux {
                                        pins = "gpio8";
                                        function = "gpio";
                                };

                                config {
                                        pins = "gpio8";
                                        drive-strength = <2>;
                                        bias-disable;
                                };
                        };
                };

                pmx_ts_release {
                        ts_release: ts_release {
                                mux {
                                        pins = "gpio9", "gpio8";
                                        function = "gpio";
                                };

                                config {
                                        pins = "gpio9", "gpio8";
                                        drive-strength = <2>;
                                        bias-disable;
                                };
                        };
                };
#endif
        te_gpio: te-default {
                pins = "gpio10";
                function = "mdp_vsync";
                drive-strength = <2>;   /* 2 mA */
                bias-pull-down;         /* PULL DOWN */
        };
};

/* override later by pm6150.dtsi */
&pm6150_lsid1 {
		pm6150_vib: vibrator@5300 {
			compatible = "qcom,pm6150-vib", "qcom,pmi632-vib";
			reg = <0x5300>;
			status = "disabled";
		};
};

&pm6150_vib {
	status = "okay";
};

&ufs_mem_hc { status = "disabled"; };
&ufs_mem_phy { status = "disabled"; };

&mpss_gpr { status = "disabled"; };
